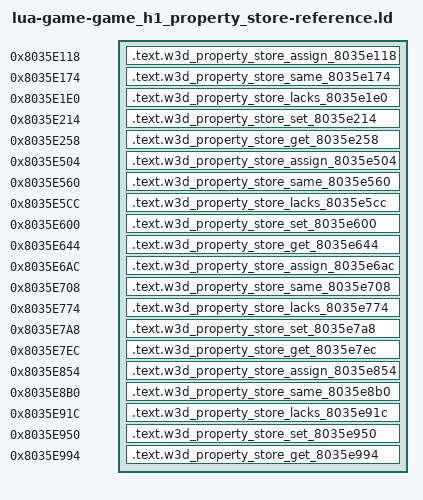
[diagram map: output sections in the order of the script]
/* Generated reference-only placements. All bodies are source-built. */
OUTPUT_FORMAT("elf32-powerpc")
OUTPUT_ARCH(powerpc)
ENTRY(w3d_property_store_assign_8035e118)
_SDA_BASE_ = 0x804b2540;
_SDA2_BASE_ = 0x804c2540;
w3d_property_insert_802078b4 = 0x802078b4;
w3d_s21_find_data_80207950 = 0x80207950;
SECTIONS {
  .text.w3d_property_store_assign_8035e118 0x8035e118 : { *(.text.w3d_property_store_assign_8035e118) }
  .text.w3d_property_store_same_8035e174 0x8035e174 : { *(.text.w3d_property_store_same_8035e174) }
  .text.w3d_property_store_lacks_8035e1e0 0x8035e1e0 : { *(.text.w3d_property_store_lacks_8035e1e0) }
  .text.w3d_property_store_set_8035e214 0x8035e214 : { *(.text.w3d_property_store_set_8035e214) }
  .text.w3d_property_store_get_8035e258 0x8035e258 : { *(.text.w3d_property_store_get_8035e258) }
  .text.w3d_property_store_assign_8035e504 0x8035e504 : { *(.text.w3d_property_store_assign_8035e504) }
  .text.w3d_property_store_same_8035e560 0x8035e560 : { *(.text.w3d_property_store_same_8035e560) }
  .text.w3d_property_store_lacks_8035e5cc 0x8035e5cc : { *(.text.w3d_property_store_lacks_8035e5cc) }
  .text.w3d_property_store_set_8035e600 0x8035e600 : { *(.text.w3d_property_store_set_8035e600) }
  .text.w3d_property_store_get_8035e644 0x8035e644 : { *(.text.w3d_property_store_get_8035e644) }
  .text.w3d_property_store_assign_8035e6ac 0x8035e6ac : { *(.text.w3d_property_store_assign_8035e6ac) }
  .text.w3d_property_store_same_8035e708 0x8035e708 : { *(.text.w3d_property_store_same_8035e708) }
  .text.w3d_property_store_lacks_8035e774 0x8035e774 : { *(.text.w3d_property_store_lacks_8035e774) }
  .text.w3d_property_store_set_8035e7a8 0x8035e7a8 : { *(.text.w3d_property_store_set_8035e7a8) }
  .text.w3d_property_store_get_8035e7ec 0x8035e7ec : { *(.text.w3d_property_store_get_8035e7ec) }
  .text.w3d_property_store_assign_8035e854 0x8035e854 : { *(.text.w3d_property_store_assign_8035e854) }
  .text.w3d_property_store_same_8035e8b0 0x8035e8b0 : { *(.text.w3d_property_store_same_8035e8b0) }
  .text.w3d_property_store_lacks_8035e91c 0x8035e91c : { *(.text.w3d_property_store_lacks_8035e91c) }
  .text.w3d_property_store_set_8035e950 0x8035e950 : { *(.text.w3d_property_store_set_8035e950) }
  .text.w3d_property_store_get_8035e994 0x8035e994 : { *(.text.w3d_property_store_get_8035e994) }
  /DISCARD/ : { *(.text*) *(.rodata*) *(.data*) *(.bss*) *(.sdata*) *(.sbss*) *(.comment) }
}
